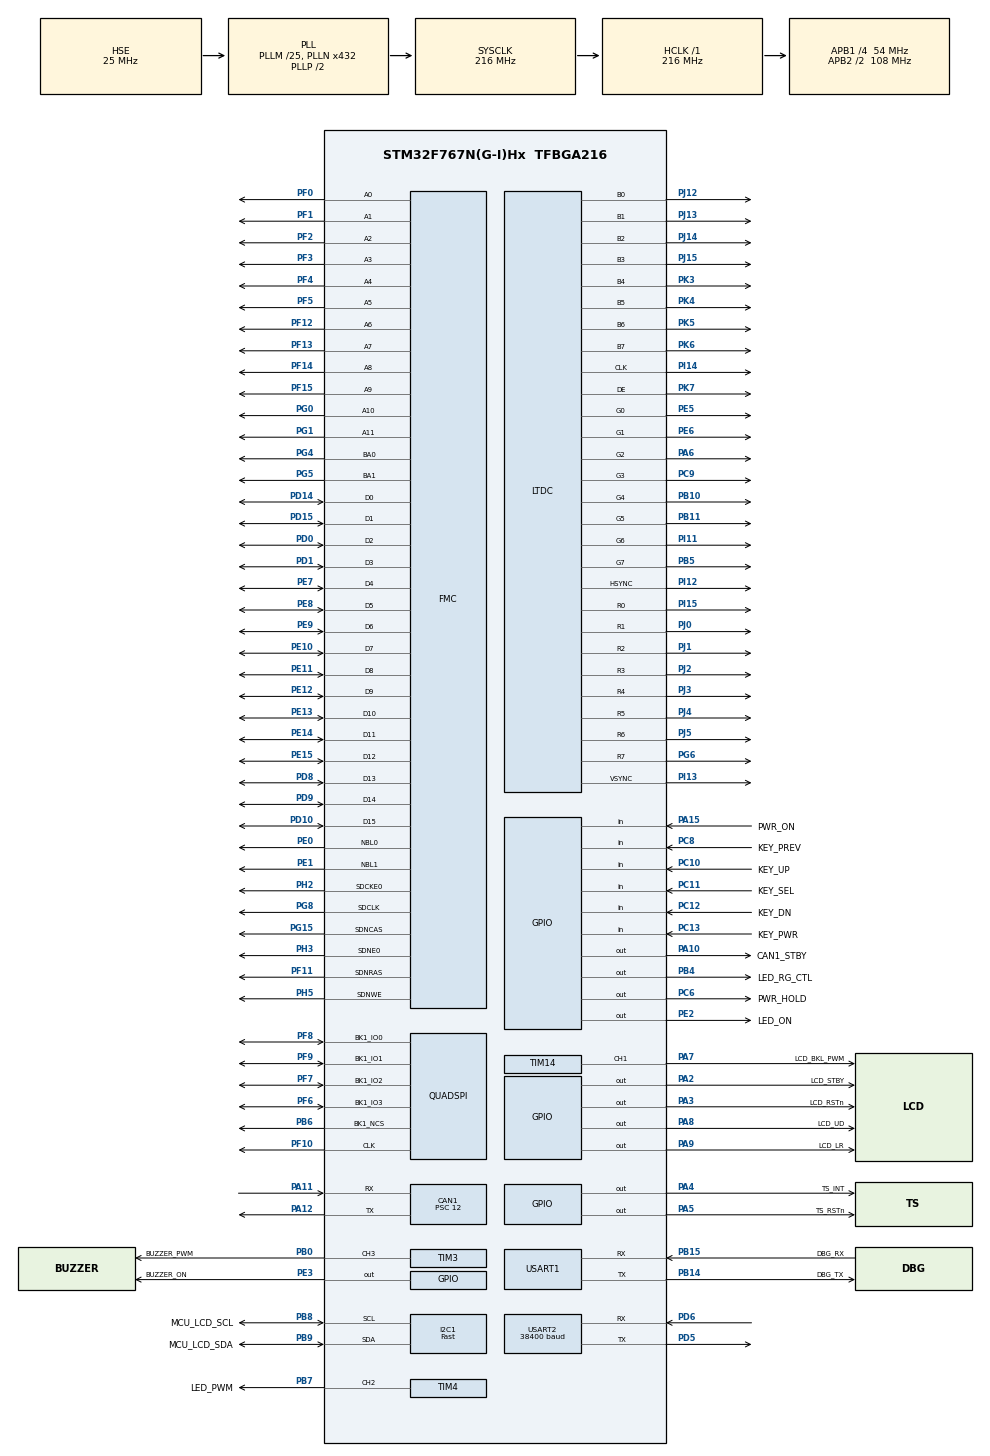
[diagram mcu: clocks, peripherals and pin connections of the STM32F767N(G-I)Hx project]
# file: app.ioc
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CAN1.ABOM=ENABLE
CAN1.AWUM=ENABLE
CAN1.BS1=CAN_BS1_15TQ
CAN1.BS2=CAN_BS2_2TQ
CAN1.CalculateBaudRate=250000
CAN1.CalculateTimeBit=4000
CAN1.CalculateTimeQuantum=222.22222222222223
CAN1.NART=ENABLE
CAN1.Prescaler=12
CAN1.TXFP=ENABLE
CORTEX_M7.CPU_DCache=Enabled
CORTEX_M7.CPU_ICache=Enabled
CORTEX_M7.MPU_Control=__NULL
CORTEX_M7.PREFETCH_ENABLE=1
CRC.InputDataFormat=CRC_INPUTDATA_FORMAT_WORDS
DMA2D.ColorMode=DMA2D_OUTPUT_RGB565
DMA2D.InputColorModeForeground=DMA2D_INPUT_RGB565
DMA2D.Mode=DMA2D_M2M
FMC.CASLatency1=FMC_SDRAM_CAS_LATENCY_3
FMC.ColumnBitsNumber1=FMC_SDRAM_COLUMN_BITS_NUM_9
FMC.ExitSelfRefreshDelay1=7
FMC.LoadToActiveDelay1=2
FMC.RCDDelay1=3
FMC.RPDelay1=3
FMC.RPDelay2=3
FMC.ReadBurst1=FMC_SDRAM_RBURST_ENABLE
FMC.RowCycleDelay1=10
FMC.RowCycleDelay2=10
FMC.SDClockPeriod1=FMC_SDRAM_CLOCK_PERIOD_2
FMC.SelfRefreshTime1=7
FMC.WriteProtection1=FMC_SDRAM_WRITE_PROTECTION_DISABLE
FMC.WriteRecoveryTime1=4
FREERTOS.Queues01=EcoQueueUART1,256,uint8_t,0,Static,EcoQueueUART1Buffer,EcoQueueUART1CtrlBlock;EcoQueueNMEA2KRX1,32,uint8_t,0,Static,EcoQueueNMEA2KRX1Buffer,EcoQueueNMEA2KRX1CtrlBlock;EcoQueueNMEA2KTX1,384,uint8_t,0,Static,EcoQueueNMEA2KTX1Buffer,EcoQueueNMEA2KTX1CtrlBlock
FREERTOS.Tasks01=EcoTaskMain,24,1024,runEcoTaskMain,As weak,NULL,Dynamic,NULL,NULL;EcoTaskUART,24,1024,runEcoTaskUART,As external,NULL,Dynamic,NULL,NULL;EcoTaskNMEA2KRx,24,1024,runEcoTaskNMEA2KRx,As external,NULL,Dynamic,NULL,NULL;EcoTaskNMEA2KTx,24,1024,runEcoTaskNMEA2KTx,As external,NULL,Dynamic,NULL,NULL;EcoTaskFlash,24,1024,runEcoTaskFlash,As external,NULL,Dynamic,NULL,NULL;EcoTaskKey,24,1024,runEcoTaskKey,As external,NULL,Dynamic,NULL,NULL;EcoTaskTGFX,24,4096,runEcoTaskTGFX,As external,NULL,Dynamic,NULL,NULL;EcoTackSync,24,1024,runEcoTaskSync,As external,NULL,Dynamic,NULL,NULL;EcoTaskControl,24,1024,runEcoTaskControl,As external,NULL,Dynamic,NULL,NULL
FREERTOS.configMINIMAL_STACK_SIZE=128
FREERTOS.configTOTAL_HEAP_SIZE=0xD000
FREERTOS.configUSE_NEWLIB_REENTRANT=1
I2C1.I2C_Speed_Mode=I2C_Fast
I2C1.Timing=0x6000030D
LTDC.ActiveW=800
LTDC.Alpha_L0=255
LTDC.Alpha_L1=255
LTDC.FBStartAdress_L0=0xC0000000
LTDC.FBStartAdress_L1=0xC0100000
LTDC.HBP=10
LTDC.HFP=10
LTDC.HSPolarity=LTDC_HSPOLARITY_AH
LTDC.HSync=14
LTDC.ImageHeight_L0=480
LTDC.ImageHeight_L1=480
LTDC.ImageWidth_L0=800
LTDC.Layers=0
LTDC.PCPolarity=LTDC_PCPOLARITY_IPC
LTDC.PixelFormat_L0=LTDC_PIXEL_FORMAT_RGB565
LTDC.PixelFormat_L1=LTDC_PIXEL_FORMAT_RGB565
LTDC.VBP=7
LTDC.VFP=7
LTDC.VSPolarity=LTDC_VSPOLARITY_AH
LTDC.VSync=7
LTDC.WindowX1_L0=800
LTDC.WindowX1_L1=800
LTDC.WindowY1_L0=480
LTDC.WindowY1_L1=480
Mcu.Family=STM32F7
Mcu.Name=STM32F767N(G-I)Hx
Mcu.Package=TFBGA216
NVIC.CAN1_RX0_IRQn=true\:5\:0\:false\:false\:true\:true\:true\:true\:true
NVIC.CAN1_TX_IRQn=true\:5\:0\:false\:false\:true\:true\:true\:true\:true
NVIC.DMA2D_IRQn=true\:5\:0\:false\:false\:true\:true\:true\:true\:true
NVIC.I2C1_EV_IRQn=true\:5\:0\:false\:false\:true\:true\:true\:true\:true
NVIC.LTDC_IRQn=true\:5\:0\:false\:false\:true\:true\:true\:true\:true
NVIC.PriorityGroup=NVIC_PRIORITYGROUP_4
NVIC.TIM6_DAC_IRQn=true\:15\:0\:false\:false\:true\:false\:false\:true\:true
NVIC.TIM7_IRQn=true\:5\:0\:false\:false\:true\:true\:true\:true\:true
NVIC.TimeBase=TIM6_DAC_IRQn
NVIC.TimeBaseIP=TIM6
NVIC.USART1_IRQn=true\:5\:0\:false\:false\:true\:true\:true\:true\:true
NVIC.USART2_IRQn=true\:5\:0\:false\:false\:true\:true\:true\:true\:true
PA10.GPIO_Label=CAN1_STBY
PA10.Signal=GPIO_Output
PA11.Mode=CAN_Activate
PA11.Signal=CAN1_RX
PA12.Mode=CAN_Activate
PA12.Signal=CAN1_TX
PA13.Mode=Trace_Asynchronous_SW
PA13.Signal=SYS_JTMS-SWDIO
PA14.Mode=Trace_Asynchronous_SW
PA14.Signal=SYS_JTCK-SWCLK
PA15.GPIO_Label=PWR_ON
PA15.Signal=GPIO_Input
PA2.GPIO_Label=LCD_STBY
PA2.Signal=GPIO_Output
PA3.GPIO_Label=LCD_RSTn
PA3.PinState=GPIO_PIN_RESET
PA3.Signal=GPIO_Output
PA4.GPIO_Label=TS_INT
PA4.Signal=GPIO_Output
PA5.GPIO_Label=TS_RSTn
PA5.Signal=GPIO_Output
PA6.Mode=RGB888
PA6.Signal=LTDC_G2
PA7.GPIO_Label=LCD_BKL_PWM
PA7.Signal=S_TIM14_CH1
PA8.GPIO_Label=LCD_UD
PA8.PinState=GPIO_PIN_SET
PA8.Signal=GPIO_Output
PA9.GPIO_Label=LCD_LR
PA9.PinState=GPIO_PIN_SET
PA9.Signal=GPIO_Output
PB0.GPIO_Label=BUZZER_PWM
PB0.Signal=S_TIM3_CH3
PB10.Mode=RGB888
PB10.Signal=LTDC_G4
PB11.Mode=RGB888
PB11.Signal=LTDC_G5
PB14.GPIO_Label=DBG_TX
PB14.Mode=Asynchronous
PB14.Signal=USART1_TX
PB15.GPIO_Label=DBG_RX
PB15.Mode=Asynchronous
PB15.Signal=USART1_RX
PB3.Mode=Trace_Asynchronous_SW
PB3.Signal=SYS_JTDO-SWO
PB4.GPIO_Label=LED_RG_CTL
PB4.Signal=GPIO_Output
PB5.Mode=RGB888
PB5.Signal=LTDC_G7
PB6.GPIO_PuPd=GPIO_PULLUP
PB6.Mode=Single Bank 1
PB6.Signal=QUADSPI_BK1_NCS
PB7.GPIO_Label=LED_PWM
PB7.Signal=S_TIM4_CH2
PB8.GPIO_Label=MCU_LCD_SCL
PB8.Mode=I2C
PB8.Signal=I2C1_SCL
PB9.GPIO_Label=MCU_LCD_SDA
PB9.Mode=I2C
PB9.Signal=I2C1_SDA
PC10.GPIO_Label=KEY_UP
PC10.Signal=GPIO_Input
PC11.GPIO_Label=KEY_SEL
PC11.Signal=GPIO_Input
PC12.GPIO_Label=KEY_DN
PC12.Signal=GPIO_Input
PC13.GPIO_Label=KEY_PWR
PC13.GPIO_PuPd=GPIO_PULLUP
PC13.Signal=GPIO_Input
PC6.GPIO_Label=PWR_HOLD
PC6.Signal=GPIO_Output
PC8.GPIO_Label=KEY_PREV
PC8.Signal=GPIO_Input
PC9.Mode=RGB888
PC9.Signal=LTDC_G3
PD0.Signal=FMC_D2_DA2
PD1.Signal=FMC_D3_DA3
PD10.Signal=FMC_D15_DA15
PD14.Signal=FMC_D0_DA0
PD15.Signal=FMC_D1_DA1
PD5.Mode=Asynchronous
PD5.Signal=USART2_TX
PD6.Mode=Asynchronous
PD6.Signal=USART2_RX
PD8.Signal=FMC_D13_DA13
PD9.Signal=FMC_D14_DA14
PE0.Signal=FMC_NBL0
PE1.Signal=FMC_NBL1
PE10.Signal=FMC_D7_DA7
PE11.Signal=FMC_D8_DA8
PE12.Signal=FMC_D9_DA9
PE13.Signal=FMC_D10_DA10
PE14.Signal=FMC_D11_DA11
PE15.Signal=FMC_D12_DA12
PE2.GPIO_Label=LED_ON
PE2.PinState=GPIO_PIN_RESET
PE2.Signal=GPIO_Output
PE3.GPIO_Label=BUZZER_ON
PE3.GPIO_Speed=GPIO_SPEED_FREQ_HIGH
PE3.Signal=GPIO_Output
PE5.Mode=RGB888
PE5.Signal=LTDC_G0
PE6.Mode=RGB888
PE6.Signal=LTDC_G1
PE7.Signal=FMC_D4_DA4
PE8.Signal=FMC_D5_DA5
PE9.Signal=FMC_D6_DA6
PF0.Signal=FMC_A0
PF1.Signal=FMC_A1
PF10.Mode=Single Bank 1
PF10.Signal=QUADSPI_CLK
PF11.Signal=FMC_SDNRAS
PF12.Signal=FMC_A6
PF13.Signal=FMC_A7
PF14.Signal=FMC_A8
PF15.Signal=FMC_A9
PF2.Signal=FMC_A2
PF3.Signal=FMC_A3
PF4.Signal=FMC_A4
PF5.Signal=FMC_A5
PF6.Mode=Single Bank 1
PF6.Signal=QUADSPI_BK1_IO3
PF7.Mode=Single Bank 1
PF7.Signal=QUADSPI_BK1_IO2
PF8.Mode=Single Bank 1
PF8.Signal=QUADSPI_BK1_IO0
PF9.Mode=Single Bank 1
PF9.Signal=QUADSPI_BK1_IO1
PG0.Signal=FMC_A10
PG1.Signal=FMC_A11
PG15.Signal=FMC_SDNCAS
PG4.Signal=FMC_A14_BA0
PG5.Signal=FMC_A15_BA1
PG6.Mode=RGB888
PG6.Signal=LTDC_R7
PG8.Signal=FMC_SDCLK
PH0/OSC_IN.Mode=HSE-External-Oscillator
PH0/OSC_IN.Signal=RCC_OSC_IN
PH1/OSC_OUT.Mode=HSE-External-Oscillator
PH1/OSC_OUT.Signal=RCC_OSC_OUT
PH2.Mode=SdramChipSelect1_1
PH2.Signal=FMC_SDCKE0
PH3.Mode=SdramChipSelect1_1
PH3.Signal=FMC_SDNE0
PH5.Signal=FMC_SDNWE
PI11.Mode=RGB888
PI11.Signal=LTDC_G6
PI12.GPIO_Speed=GPIO_SPEED_FREQ_LOW
PI12.Mode=RGB888
PI12.Signal=LTDC_HSYNC
PI13.GPIO_Speed=GPIO_SPEED_FREQ_LOW
PI13.Mode=RGB888
PI13.Signal=LTDC_VSYNC
PI14.GPIO_Speed=GPIO_SPEED_FREQ_LOW
PI14.Mode=RGB888
PI14.Signal=LTDC_CLK
PI15.Mode=RGB888
PI15.Signal=LTDC_R0
PJ0.Mode=RGB888
PJ0.Signal=LTDC_R1
PJ1.Mode=RGB888
PJ1.Signal=LTDC_R2
PJ12.Mode=RGB888
PJ12.Signal=LTDC_B0
PJ13.Mode=RGB888
PJ13.Signal=LTDC_B1
PJ14.Mode=RGB888
PJ14.Signal=LTDC_B2
PJ15.Mode=RGB888
PJ15.Signal=LTDC_B3
PJ2.Mode=RGB888
PJ2.Signal=LTDC_R3
PJ3.Mode=RGB888
PJ3.Signal=LTDC_R4
PJ4.Mode=RGB888
PJ4.Signal=LTDC_R5
PJ5.Mode=RGB888
PJ5.Signal=LTDC_R6
PK3.Mode=RGB888
PK3.Signal=LTDC_B4
PK4.Mode=RGB888
PK4.Signal=LTDC_B5
PK5.Mode=RGB888
PK5.Signal=LTDC_B6
PK6.Mode=RGB888
PK6.Signal=LTDC_B7
PK7.Mode=RGB888
PK7.Signal=LTDC_DE
ProjectManager.HeapSize=0x1000
ProjectManager.StackSize=0x1000
ProjectManager.TargetToolchain=STM32CubeIDE
QUADSPI.ChipSelectHighTime=QSPI_CS_HIGH_TIME_6_CYCLE
QUADSPI.ClockPrescaler=1
QUADSPI.FifoThreshold=6
QUADSPI.FlashSize=24
QUADSPI.SampleShifting=QSPI_SAMPLE_SHIFTING_HALFCYCLE
RCC.AHBFreq_Value=216000000
RCC.APB1CLKDivider=RCC_HCLK_DIV4
RCC.APB1Freq_Value=54000000
RCC.APB1TimFreq_Value=108000000
RCC.APB2CLKDivider=RCC_HCLK_DIV2
RCC.APB2Freq_Value=108000000
RCC.APB2TimFreq_Value=216000000
RCC.CortexFreq_Value=216000000
RCC.HCLKFreq_Value=216000000
RCC.HSE_VALUE=25000000
RCC.HSI_VALUE=16000000
RCC.LSE_VALUE=32768
RCC.PLLM=25
RCC.PLLN=432
RCC.PLLSAIN=400
RCC.PLLSAIR=4
RCC.PLLSAIRDiv=RCC_PLLSAIDIVR_4
RCC.PLLSourceVirtual=RCC_PLLSOURCE_HSE
RCC.SYSCLKFreq_VALUE=216000000
RCC.SYSCLKSource=RCC_SYSCLKSOURCE_PLLCLK
RCC.USBFreq_Value=216000000
RCC.VCOOutputFreq_Value=432000000
SH.FMC_A0.0=FMC_A0,12b-sda1
SH.FMC_A1.0=FMC_A1,12b-sda1
SH.FMC_A10.0=FMC_A10,12b-sda1
SH.FMC_A11.0=FMC_A11,12b-sda1
SH.FMC_A14_BA0.0=FMC_BA0,FourSdramBanks1
SH.FMC_A15_BA1.0=FMC_BA1,FourSdramBanks1
SH.FMC_A2.0=FMC_A2,12b-sda1
SH.FMC_A3.0=FMC_A3,12b-sda1
SH.FMC_A4.0=FMC_A4,12b-sda1
SH.FMC_A5.0=FMC_A5,12b-sda1
SH.FMC_A6.0=FMC_A6,12b-sda1
SH.FMC_A7.0=FMC_A7,12b-sda1
SH.FMC_A8.0=FMC_A8,12b-sda1
SH.FMC_A9.0=FMC_A9,12b-sda1
SH.FMC_D0_DA0.0=FMC_D0,sd-16b-d1
SH.FMC_D10_DA10.0=FMC_D10,sd-16b-d1
SH.FMC_D11_DA11.0=FMC_D11,sd-16b-d1
SH.FMC_D12_DA12.0=FMC_D12,sd-16b-d1
SH.FMC_D13_DA13.0=FMC_D13,sd-16b-d1
SH.FMC_D14_DA14.0=FMC_D14,sd-16b-d1
SH.FMC_D15_DA15.0=FMC_D15,sd-16b-d1
SH.FMC_D1_DA1.0=FMC_D1,sd-16b-d1
SH.FMC_D2_DA2.0=FMC_D2,sd-16b-d1
SH.FMC_D3_DA3.0=FMC_D3,sd-16b-d1
SH.FMC_D4_DA4.0=FMC_D4,sd-16b-d1
SH.FMC_D5_DA5.0=FMC_D5,sd-16b-d1
SH.FMC_D6_DA6.0=FMC_D6,sd-16b-d1
SH.FMC_D7_DA7.0=FMC_D7,sd-16b-d1
SH.FMC_D8_DA8.0=FMC_D8,sd-16b-d1
SH.FMC_D9_DA9.0=FMC_D9,sd-16b-d1
SH.FMC_NBL0.0=FMC_NBL0,Sd2ByteEnable1
SH.FMC_NBL1.0=FMC_NBL1,Sd2ByteEnable1
SH.FMC_SDCLK.0=FMC_SDCLK,12b-sda1
SH.FMC_SDNCAS.0=FMC_SDNCAS,12b-sda1
SH.FMC_SDNRAS.0=FMC_SDNRAS,12b-sda1
SH.FMC_SDNWE.0=FMC_SDNWE,12b-sda1
SH.S_TIM14_CH1.0=TIM14_CH1,PWM Generation1 CH1
SH.S_TIM3_CH3.0=TIM3_CH3,PWM Generation3 CH3
SH.S_TIM4_CH2.0=TIM4_CH2,PWM Generation2 CH2
STMicroelectronics.X-CUBE-TOUCHGFX.4.25.0.ApplicationCcGraphicsJjApplication=TouchGFXOoGenerator
STMicroelectronics.X-CUBE-TOUCHGFX.4.25.0.tgfx_address1=0xC0000000
STMicroelectronics.X-CUBE-TOUCHGFX.4.25.0.tgfx_address2=0xC0100000
STMicroelectronics.X-CUBE-TOUCHGFX.4.25.0.tgfx_buffering_strategy=Double
STMicroelectronics.X-CUBE-TOUCHGFX.4.25.0.tgfx_display_interface=disp_ltdc
STMicroelectronics.X-CUBE-TOUCHGFX.4.25.0.tgfx_hardware_accelerator=dma_2d
STMicroelectronics.X-CUBE-TOUCHGFX.4.25.0.tgfx_location=By Address
STMicroelectronics.X-CUBE-TOUCHGFX.4.25.0.tgfx_vector_rendering=Disabled
STMicroelectronics.X-CUBE-TOUCHGFX.4.25.0.tgfx_vsync=vsync_ltdc
STMicroelectronics.X-CUBE-TOUCHGFX.4.25.0_IsPackSelfContextualization=true
TIM14.Channel=TIM_CHANNEL_1
TIM14.Period=100-1
TIM14.Prescaler=108-1
TIM14.Pulse=100-1
TIM3.AutoReloadPreload=TIM_AUTORELOAD_PRELOAD_ENABLE
TIM3.Channel-PWM\ Generation3\ CH3=TIM_CHANNEL_3
TIM3.Period=250-1
TIM3.Prescaler=108-1
TIM3.Pulse-PWM\ Generation3\ CH3=0
TIM4.AutoReloadPreload=TIM_AUTORELOAD_PRELOAD_ENABLE
TIM4.Channel-PWM\ Generation2\ CH2=TIM_CHANNEL_2
TIM4.Period=32768-1
TIM4.Prescaler=33-1
TIM4.Pulse-PWM\ Generation2\ CH2=256
TIM7.AutoReloadPreload=TIM_AUTORELOAD_PRELOAD_ENABLE
TIM7.Period=10000-1
TIM7.Prescaler=10800-1
USART1.VirtualMode-Asynchronous=VM_ASYNC
USART2.BaudRate=38400
USART2.VirtualMode-Asynchronous=VM_ASYNC
VP_CRC_VS_CRC.Mode=CRC_Activate
VP_DMA2D_VS_DMA2D.Mode=DMA2D_Activate
VP_FREERTOS_VS_CMSIS_V2.Mode=CMSIS_V2
VP_STMicroelectronics.X-CUBE-TOUCHGFX_VS_GraphicsJjApplication_4.25.0.Mode=GraphicsJjApplication
VP_SYS_VS_tim6.Mode=TIM6
VP_TIM14_VS_ClockSourceINT.Mode=Enable_Timer
VP_TIM3_VS_ClockSourceINT.Mode=Internal
VP_TIM4_VS_ClockSourceINT.Mode=Internal
VP_TIM7_VS_ClockSourceINT.Mode=Enable_Timer
board=custom

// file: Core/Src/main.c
/* USER CODE BEGIN Header */
/**
  ******************************************************************************
  * @file           : main.c
  * @brief          : Main program body
  ******************************************************************************
  * @attention
  *
  * Copyright (c) 2023 STMicroelectronics.
  * All rights reserved.
  *
  * This software is licensed under terms that can be found in the LICENSE file
  * in the root directory of this software component.
  * If no LICENSE file comes with this software, it is provided AS-IS.
  *
  ******************************************************************************
  */
/* USER CODE END Header */
#include "main.h"
#include "cmsis_os.h"
#include "app_touchgfx.h"

/* USER CODE BEGIN Includes */
#include "eco.h"
/* USER CODE END Includes */

typedef StaticQueue_t osStaticMessageQDef_t;

CAN_HandleTypeDef hcan1;

CRC_HandleTypeDef hcrc;

DMA2D_HandleTypeDef hdma2d;

I2C_HandleTypeDef hi2c1;

LTDC_HandleTypeDef hltdc;

QSPI_HandleTypeDef hqspi;

TIM_HandleTypeDef htim3;
TIM_HandleTypeDef htim4;
TIM_HandleTypeDef htim7;
TIM_HandleTypeDef htim14;

UART_HandleTypeDef huart1;
UART_HandleTypeDef huart2;

SDRAM_HandleTypeDef hsdram1;

/* Definitions for EcoTaskMain */
osThreadId_t EcoTaskMainHandle;
const osThreadAttr_t EcoTaskMain_attributes = {
  .name = "EcoTaskMain",
  .stack_size = 1024 * 4,
  .priority = (osPriority_t) osPriorityNormal,
};
/* Definitions for EcoTaskUART */
osThreadId_t EcoTaskUARTHandle;
const osThreadAttr_t EcoTaskUART_attributes = {
  .name = "EcoTaskUART",
  .stack_size = 1024 * 4,
  .priority = (osPriority_t) osPriorityNormal,
};
/* Definitions for EcoTaskNMEA2KRx */
osThreadId_t EcoTaskNMEA2KRxHandle;
const osThreadAttr_t EcoTaskNMEA2KRx_attributes = {
  .name = "EcoTaskNMEA2KRx",
  .stack_size = 1024 * 4,
  .priority = (osPriority_t) osPriorityNormal,
};
/* Definitions for EcoTaskNMEA2KTx */
osThreadId_t EcoTaskNMEA2KTxHandle;
const osThreadAttr_t EcoTaskNMEA2KTx_attributes = {
  .name = "EcoTaskNMEA2KTx",
  .stack_size = 1024 * 4,
  .priority = (osPriority_t) osPriorityNormal,
};
/* Definitions for EcoTaskFlash */
osThreadId_t EcoTaskFlashHandle;
const osThreadAttr_t EcoTaskFlash_attributes = {
  .name = "EcoTaskFlash",
  .stack_size = 1024 * 4,
  .priority = (osPriority_t) osPriorityNormal,
};
/* Definitions for EcoTaskKey */
osThreadId_t EcoTaskKeyHandle;
const osThreadAttr_t EcoTaskKey_attributes = {
  .name = "EcoTaskKey",
  .stack_size = 1024 * 4,
  .priority = (osPriority_t) osPriorityNormal,
};
/* Definitions for EcoTaskTGFX */
osThreadId_t EcoTaskTGFXHandle;
const osThreadAttr_t EcoTaskTGFX_attributes = {
  .name = "EcoTaskTGFX",
  .stack_size = 4096 * 4,
  .priority = (osPriority_t) osPriorityNormal,
};
/* Definitions for EcoTackSync */
osThreadId_t EcoTackSyncHandle;
const osThreadAttr_t EcoTackSync_attributes = {
  .name = "EcoTackSync",
  .stack_size = 1024 * 4,
  .priority = (osPriority_t) osPriorityNormal,
};
/* Definitions for EcoTaskControl */
osThreadId_t EcoTaskControlHandle;
const osThreadAttr_t EcoTaskControl_attributes = {
  .name = "EcoTaskControl",
  .stack_size = 1024 * 4,
  .priority = (osPriority_t) osPriorityNormal,
};
/* Definitions for EcoQueueUART1 */
osMessageQueueId_t EcoQueueUART1Handle;
uint8_t EcoQueueUART1Buffer[ 256 * sizeof( uint8_t ) ];
osStaticMessageQDef_t EcoQueueUART1CtrlBlock;
const osMessageQueueAttr_t EcoQueueUART1_attributes = {
  .name = "EcoQueueUART1",
  .cb_mem = &EcoQueueUART1CtrlBlock,
  .cb_size = sizeof(EcoQueueUART1CtrlBlock),
  .mq_mem = &EcoQueueUART1Buffer,
  .mq_size = sizeof(EcoQueueUART1Buffer)
};
/* Definitions for EcoQueueNMEA2KRX1 */
osMessageQueueId_t EcoQueueNMEA2KRX1Handle;
uint8_t EcoQueueNMEA2KRX1Buffer[ 32 * sizeof( uint8_t ) ];
osStaticMessageQDef_t EcoQueueNMEA2KRX1CtrlBlock;
const osMessageQueueAttr_t EcoQueueNMEA2KRX1_attributes = {
  .name = "EcoQueueNMEA2KRX1",
  .cb_mem = &EcoQueueNMEA2KRX1CtrlBlock,
  .cb_size = sizeof(EcoQueueNMEA2KRX1CtrlBlock),
  .mq_mem = &EcoQueueNMEA2KRX1Buffer,
  .mq_size = sizeof(EcoQueueNMEA2KRX1Buffer)
};
/* Definitions for EcoQueueNMEA2KTX1 */
osMessageQueueId_t EcoQueueNMEA2KTX1Handle;
uint8_t EcoQueueNMEA2KTX1Buffer[ 384 * sizeof( uint8_t ) ];
osStaticMessageQDef_t EcoQueueNMEA2KTX1CtrlBlock;
const osMessageQueueAttr_t EcoQueueNMEA2KTX1_attributes = {
  .name = "EcoQueueNMEA2KTX1",
  .cb_mem = &EcoQueueNMEA2KTX1CtrlBlock,
  .cb_size = sizeof(EcoQueueNMEA2KTX1CtrlBlock),
  .mq_mem = &EcoQueueNMEA2KTX1Buffer,
  .mq_size = sizeof(EcoQueueNMEA2KTX1Buffer)
};

void SystemClock_Config(void);
static void MX_GPIO_Init(void);
static void MX_USART1_UART_Init(void);
static void MX_I2C1_Init(void);
static void MX_CAN1_Init(void);
static void MX_QUADSPI_Init(void);
static void MX_CRC_Init(void);
static void MX_DMA2D_Init(void);
static void MX_FMC_Init(void);
static void MX_LTDC_Init(void);
static void MX_TIM3_Init(void);
static void MX_USART2_UART_Init(void);
static void MX_TIM4_Init(void);
static void MX_TIM7_Init(void);
static void MX_TIM14_Init(void);
void runEcoTaskMain(void *argument);
extern void runEcoTaskUART(void *argument);
extern void runEcoTaskNMEA2KRx(void *argument);
extern void runEcoTaskNMEA2KTx(void *argument);
extern void runEcoTaskFlash(void *argument);
extern void runEcoTaskKey(void *argument);
extern void runEcoTaskTGFX(void *argument);
extern void runEcoTaskSync(void *argument);
extern void runEcoTaskControl(void *argument);

/* USER CODE BEGIN PFP */
void SystemClock_pwrsav_Config(void);
/* USER CODE END PFP */

int main(void)
{

  /* Enable the CPU Cache */

  /* Enable I-Cache---------------------------------------------------------*/
  SCB_EnableICache();

  /* Enable D-Cache---------------------------------------------------------*/
  SCB_EnableDCache();

  /* MCU Configuration--------------------------------------------------------*/

  /* Reset of all peripherals, Initializes the Flash interface and the Systick. */
  HAL_Init();

  /* Configure the system clock */
  SystemClock_Config();

  /* Initialize all configured peripherals */
  MX_GPIO_Init();
  MX_USART1_UART_Init();
  MX_I2C1_Init();
  MX_CAN1_Init();
  MX_QUADSPI_Init();
  MX_CRC_Init();
  MX_DMA2D_Init();
  MX_FMC_Init();
  MX_LTDC_Init();
  MX_TIM3_Init();
  MX_USART2_UART_Init();
  MX_TIM4_Init();
  MX_TIM7_Init();
  MX_TIM14_Init();
  MX_TouchGFX_Init();
  /* Call PreOsInit function */
  MX_TouchGFX_PreOSInit();

  /* Init scheduler */
  osKernelInitialize();

  /* Create the queue(s) */
  /* creation of EcoQueueUART1 */
  EcoQueueUART1Handle = osMessageQueueNew (256, sizeof(uint8_t), &EcoQueueUART1_attributes);

  /* creation of EcoQueueNMEA2KRX1 */
  EcoQueueNMEA2KRX1Handle = osMessageQueueNew (32, sizeof(uint8_t), &EcoQueueNMEA2KRX1_attributes);

  /* creation of EcoQueueNMEA2KTX1 */
  EcoQueueNMEA2KTX1Handle = osMessageQueueNew (384, sizeof(uint8_t), &EcoQueueNMEA2KTX1_attributes);

  /* Create the thread(s) */
  /* creation of EcoTaskMain */
  EcoTaskMainHandle = osThreadNew(runEcoTaskMain, NULL, &EcoTaskMain_attributes);

  /* creation of EcoTaskUART */
  EcoTaskUARTHandle = osThreadNew(runEcoTaskUART, NULL, &EcoTaskUART_attributes);

  /* creation of EcoTaskNMEA2KRx */
  EcoTaskNMEA2KRxHandle = osThreadNew(runEcoTaskNMEA2KRx, NULL, &EcoTaskNMEA2KRx_attributes);

  /* creation of EcoTaskNMEA2KTx */
  EcoTaskNMEA2KTxHandle = osThreadNew(runEcoTaskNMEA2KTx, NULL, &EcoTaskNMEA2KTx_attributes);

  /* creation of EcoTaskFlash */
  EcoTaskFlashHandle = osThreadNew(runEcoTaskFlash, NULL, &EcoTaskFlash_attributes);

  /* creation of EcoTaskKey */
  EcoTaskKeyHandle = osThreadNew(runEcoTaskKey, NULL, &EcoTaskKey_attributes);

  /* creation of EcoTaskTGFX */
  EcoTaskTGFXHandle = osThreadNew(runEcoTaskTGFX, NULL, &EcoTaskTGFX_attributes);

  /* creation of EcoTackSync */
  EcoTackSyncHandle = osThreadNew(runEcoTaskSync, NULL, &EcoTackSync_attributes);

  /* creation of EcoTaskControl */
  EcoTaskControlHandle = osThreadNew(runEcoTaskControl, NULL, &EcoTaskControl_attributes);

  /* Start scheduler */
  osKernelStart();

  /* We should never get here as control is now taken by the scheduler */

  /* Infinite loop */
  while (1)
  {

  }
}

void SystemClock_Config(void)
{
  RCC_OscInitTypeDef RCC_OscInitStruct = {0};
  RCC_ClkInitTypeDef RCC_ClkInitStruct = {0};

  /** Configure the main internal regulator output voltage
  */
  __HAL_RCC_PWR_CLK_ENABLE();
  __HAL_PWR_VOLTAGESCALING_CONFIG(PWR_REGULATOR_VOLTAGE_SCALE1);

  /** Initializes the RCC Oscillators according to the specified parameters
  * in the RCC_OscInitTypeDef structure.
  */
  RCC_OscInitStruct.OscillatorType = RCC_OSCILLATORTYPE_HSE;
  RCC_OscInitStruct.HSEState = RCC_HSE_ON;
  RCC_OscInitStruct.PLL.PLLState = RCC_PLL_ON;
  RCC_OscInitStruct.PLL.PLLSource = RCC_PLLSOURCE_HSE;
  RCC_OscInitStruct.PLL.PLLM = 25;
  RCC_OscInitStruct.PLL.PLLN = 432;
  RCC_OscInitStruct.PLL.PLLP = RCC_PLLP_DIV2;
  RCC_OscInitStruct.PLL.PLLQ = 2;
  RCC_OscInitStruct.PLL.PLLR = 2;
  if (HAL_RCC_OscConfig(&RCC_OscInitStruct) != HAL_OK)
  {
    Error_Handler();
  }

  /** Activate the Over-Drive mode
  */
  if (HAL_PWREx_EnableOverDrive() != HAL_OK)
  {
    Error_Handler();
  }

  /** Initializes the CPU, AHB and APB buses clocks
  */
  RCC_ClkInitStruct.ClockType = RCC_CLOCKTYPE_HCLK|RCC_CLOCKTYPE_SYSCLK
                              |RCC_CLOCKTYPE_PCLK1|RCC_CLOCKTYPE_PCLK2;
  RCC_ClkInitStruct.SYSCLKSource = RCC_SYSCLKSOURCE_PLLCLK;
  RCC_ClkInitStruct.AHBCLKDivider = RCC_SYSCLK_DIV1;
  RCC_ClkInitStruct.APB1CLKDivider = RCC_HCLK_DIV4;
  RCC_ClkInitStruct.APB2CLKDivider = RCC_HCLK_DIV2;

  if (HAL_RCC_ClockConfig(&RCC_ClkInitStruct, FLASH_LATENCY_7) != HAL_OK)
  {
    Error_Handler();
  }
}

static void MX_CAN1_Init(void)
{

  /* USER CODE BEGIN CAN1_Init 0 */
  CAN_FilterTypeDef  sFilterConfig;

  /* USER CODE END CAN1_Init 0 */

  hcan1.Instance = CAN1;
  hcan1.Init.Prescaler = 12;
  hcan1.Init.Mode = CAN_MODE_NORMAL;
  hcan1.Init.SyncJumpWidth = CAN_SJW_1TQ;
  hcan1.Init.TimeSeg1 = CAN_BS1_15TQ;
  hcan1.Init.TimeSeg2 = CAN_BS2_2TQ;
  hcan1.Init.TimeTriggeredMode = DISABLE;
  hcan1.Init.AutoBusOff = ENABLE;
  hcan1.Init.AutoWakeUp = ENABLE;
  hcan1.Init.AutoRetransmission = ENABLE;
  hcan1.Init.ReceiveFifoLocked = DISABLE;
  hcan1.Init.TransmitFifoPriority = ENABLE;
  if (HAL_CAN_Init(&hcan1) != HAL_OK)
  {
    Error_Handler();
  }
  /* USER CODE BEGIN CAN1_Init 2 */
  /* Configure the CAN Filter */
  sFilterConfig.FilterBank = 0;
  sFilterConfig.FilterMode = CAN_FILTERMODE_IDMASK;
  sFilterConfig.FilterScale = CAN_FILTERSCALE_32BIT;
  sFilterConfig.FilterIdHigh = 0x0000;
  sFilterConfig.FilterIdLow = 0x0000;
  sFilterConfig.FilterMaskIdHigh = 0x0000;
  sFilterConfig.FilterMaskIdLow = 0x0000;
  sFilterConfig.FilterFIFOAssignment = CAN_FILTER_FIFO0;
  sFilterConfig.FilterActivation = ENABLE;
  sFilterConfig.SlaveStartFilterBank = 14;

  /* Filter configuration Error */
  if(HAL_CAN_ConfigFilter(&hcan1, &sFilterConfig) != HAL_OK) Error_Handler();

  /* Start the CAN peripheral */
  if(HAL_CAN_Start(&hcan1) != HAL_OK) Error_Handler();

  /* Activate CAN RX notification */
  if (HAL_CAN_ActivateNotification(&hcan1, CAN_IT_RX_FIFO0_MSG_PENDING) != HAL_OK) Error_Handler();

  /* USER CODE END CAN1_Init 2 */

}

static void MX_CRC_Init(void)
{

  hcrc.Instance = CRC;
  hcrc.Init.DefaultPolynomialUse = DEFAULT_POLYNOMIAL_ENABLE;
  hcrc.Init.DefaultInitValueUse = DEFAULT_INIT_VALUE_ENABLE;
  hcrc.Init.InputDataInversionMode = CRC_INPUTDATA_INVERSION_NONE;
  hcrc.Init.OutputDataInversionMode = CRC_OUTPUTDATA_INVERSION_DISABLE;
  hcrc.InputDataFormat = CRC_INPUTDATA_FORMAT_WORDS;
  if (HAL_CRC_Init(&hcrc) != HAL_OK)
  {
    Error_Handler();
  }

}

static void MX_DMA2D_Init(void)
{

  hdma2d.Instance = DMA2D;
  hdma2d.Init.Mode = DMA2D_M2M;
  hdma2d.Init.ColorMode = DMA2D_OUTPUT_RGB565;
  hdma2d.Init.OutputOffset = 0;
  hdma2d.LayerCfg[1].InputOffset = 0;
  hdma2d.LayerCfg[1].InputColorMode = DMA2D_INPUT_RGB565;
  hdma2d.LayerCfg[1].AlphaMode = DMA2D_NO_MODIF_ALPHA;
  hdma2d.LayerCfg[1].InputAlpha = 0;
  hdma2d.LayerCfg[1].AlphaInverted = DMA2D_REGULAR_ALPHA;
  hdma2d.LayerCfg[1].RedBlueSwap = DMA2D_RB_REGULAR;
  if (HAL_DMA2D_Init(&hdma2d) != HAL_OK)
  {
    Error_Handler();
  }
  if (HAL_DMA2D_ConfigLayer(&hdma2d, 1) != HAL_OK)
  {
    Error_Handler();
  }

}

static void MX_I2C1_Init(void)
{

  hi2c1.Instance = I2C1;
  hi2c1.Init.Timing = 0x6000030D;
  hi2c1.Init.OwnAddress1 = 0;
  hi2c1.Init.AddressingMode = I2C_ADDRESSINGMODE_7BIT;
  hi2c1.Init.DualAddressMode = I2C_DUALADDRESS_DISABLE;
  hi2c1.Init.OwnAddress2 = 0;
  hi2c1.Init.OwnAddress2Masks = I2C_OA2_NOMASK;
  hi2c1.Init.GeneralCallMode = I2C_GENERALCALL_DISABLE;
  hi2c1.Init.NoStretchMode = I2C_NOSTRETCH_DISABLE;
  if (HAL_I2C_Init(&hi2c1) != HAL_OK)
  {
    Error_Handler();
  }

  /** Configure Analogue filter
  */
  if (HAL_I2CEx_ConfigAnalogFilter(&hi2c1, I2C_ANALOGFILTER_ENABLE) != HAL_OK)
  {
    Error_Handler();
  }

  /** Configure Digital filter
  */
  if (HAL_I2CEx_ConfigDigitalFilter(&hi2c1, 0) != HAL_OK)
  {
    Error_Handler();
  }
  /* USER CODE BEGIN I2C1_Init 2 */

  initTouchSensor();

  /* USER CODE END I2C1_Init 2 */

}

static void MX_LTDC_Init(void)
{

  LTDC_LayerCfgTypeDef pLayerCfg = {0};

  /* USER CODE BEGIN LTDC_Init 1 */
  HAL_GPIO_WritePin(LCD_RSTn_GPIO_Port, LCD_RSTn_Pin, GPIO_PIN_RESET);
  HAL_Delay(10);
  HAL_GPIO_WritePin(LCD_RSTn_GPIO_Port, LCD_RSTn_Pin, GPIO_PIN_SET);
  if(g_board_id == BOARD_ID_ACU15)
  {
      HAL_Delay(5);
      HAL_GPIO_WritePin(LCD_STBY_GPIO_Port, LCD_STBY_Pin, GPIO_PIN_SET);
  }

  /* USER CODE END LTDC_Init 1 */
  hltdc.Instance = LTDC;
  hltdc.Init.HSPolarity = LTDC_HSPOLARITY_AH;
  hltdc.Init.VSPolarity = LTDC_VSPOLARITY_AH;
  hltdc.Init.DEPolarity = LTDC_DEPOLARITY_AL;
  hltdc.Init.PCPolarity = LTDC_PCPOLARITY_IPC;
  hltdc.Init.HorizontalSync = 13;
  hltdc.Init.VerticalSync = 6;
  hltdc.Init.AccumulatedHBP = 23;
  hltdc.Init.AccumulatedVBP = 13;
  hltdc.Init.AccumulatedActiveW = 823;
  hltdc.Init.AccumulatedActiveH = 493;
  hltdc.Init.TotalWidth = 833;
  hltdc.Init.TotalHeigh = 500;
  hltdc.Init.Backcolor.Blue = 0;
  hltdc.Init.Backcolor.Green = 0;
  hltdc.Init.Backcolor.Red = 0;
  if (HAL_LTDC_Init(&hltdc) != HAL_OK)
  {
    Error_Handler();
  }
  pLayerCfg.WindowX0 = 0;
  pLayerCfg.WindowX1 = 800;
  pLayerCfg.WindowY0 = 0;
  pLayerCfg.WindowY1 = 480;
  pLayerCfg.PixelFormat = LTDC_PIXEL_FORMAT_RGB565;
  pLayerCfg.Alpha = 255;
  pLayerCfg.Alpha0 = 0;
  pLayerCfg.BlendingFactor1 = LTDC_BLENDING_FACTOR1_CA;
  pLayerCfg.BlendingFactor2 = LTDC_BLENDING_FACTOR2_CA;
  pLayerCfg.FBStartAdress = 0xC0000000;
  pLayerCfg.ImageWidth = 800;
  pLayerCfg.ImageHeight = 480;
  pLayerCfg.Backcolor.Blue = 0;
  pLayerCfg.Backcolor.Green = 0;
  pLayerCfg.Backcolor.Red = 0;
  if (HAL_LTDC_ConfigLayer(&hltdc, &pLayerCfg, 0) != HAL_OK)
  {
    Error_Handler();
  }
  /* USER CODE BEGIN LTDC_Init 2 */
  if(g_board_id == BOARD_ID_ACU10)
  {
      hltdc.Instance = LTDC;
      hltdc.Init.HSPolarity = LTDC_HSPOLARITY_AL;
      hltdc.Init.VSPolarity = LTDC_VSPOLARITY_AL;
      hltdc.Init.DEPolarity = LTDC_DEPOLARITY_AL;
      hltdc.Init.PCPolarity = LTDC_PCPOLARITY_IPC;
      hltdc.Init.HorizontalSync = 6;
      hltdc.Init.VerticalSync = 6;
      hltdc.Init.AccumulatedHBP = 13;
      hltdc.Init.AccumulatedVBP = 13;
      hltdc.Init.AccumulatedActiveW = 493;
      hltdc.Init.AccumulatedActiveH = 493;
      hltdc.Init.TotalWidth = 500;
      hltdc.Init.TotalHeigh = 500;
      hltdc.Init.Backcolor.Blue = 0;
      hltdc.Init.Backcolor.Green = 0;
      hltdc.Init.Backcolor.Red = 0;
      if (HAL_LTDC_Init(&hltdc) != HAL_OK)
      {
        Error_Handler();
      }
      pLayerCfg.WindowX0 = 0;
      pLayerCfg.WindowX1 = 480;
      pLayerCfg.WindowY0 = 0;
      pLayerCfg.WindowY1 = 480;
      pLayerCfg.PixelFormat = LTDC_PIXEL_FORMAT_RGB565;
      pLayerCfg.Alpha = 255;
      pLayerCfg.Alpha0 = 0;
      pLayerCfg.BlendingFactor1 = LTDC_BLENDING_FACTOR1_CA;
      pLayerCfg.BlendingFactor2 = LTDC_BLENDING_FACTOR2_CA;
      pLayerCfg.FBStartAdress = 0xC0000000;
      pLayerCfg.ImageWidth = 480;
      pLayerCfg.ImageHeight = 480;
      pLayerCfg.Backcolor.Blue = 0;
      pLayerCfg.Backcolor.Green = 0;
      pLayerCfg.Backcolor.Red = 0;
      if (HAL_LTDC_ConfigLayer(&hltdc, &pLayerCfg, 0) != HAL_OK)
      {
        Error_Handler();
      }
  }

//  pLayerCfg.FBStartAdress = (uint32_t)((uint32_t*)image_kitten_480x480);
//  HAL_LTDC_ConfigLayer(&hltdc, &pLayerCfg, 0);
  /* USER CODE END LTDC_Init 2 */

}

static void MX_QUADSPI_Init(void)
{

  /* QUADSPI parameter configuration*/
  hqspi.Instance = QUADSPI;
  hqspi.Init.ClockPrescaler = 1;
  hqspi.Init.FifoThreshold = 6;
  hqspi.Init.SampleShifting = QSPI_SAMPLE_SHIFTING_HALFCYCLE;
  hqspi.Init.FlashSize = 24;
  hqspi.Init.ChipSelectHighTime = QSPI_CS_HIGH_TIME_6_CYCLE;
  hqspi.Init.ClockMode = QSPI_CLOCK_MODE_0;
  hqspi.Init.FlashID = QSPI_FLASH_ID_1;
  hqspi.Init.DualFlash = QSPI_DUALFLASH_DISABLE;
  if (HAL_QSPI_Init(&hqspi) != HAL_OK)
  {
    Error_Handler();
  }
  /* USER CODE BEGIN QUADSPI_Init 2 */
  initQSPI();
  /* USER CODE END QUADSPI_Init 2 */

}

static void MX_TIM3_Init(void)
{

  TIM_ClockConfigTypeDef sClockSourceConfig = {0};
  TIM_MasterConfigTypeDef sMasterConfig = {0};
  TIM_OC_InitTypeDef sConfigOC = {0};

  htim3.Instance = TIM3;
  htim3.Init.Prescaler = 108-1;
  htim3.Init.CounterMode = TIM_COUNTERMODE_UP;
  htim3.Init.Period = 250-1;
  htim3.Init.ClockDivision = TIM_CLOCKDIVISION_DIV1;
  htim3.Init.AutoReloadPreload = TIM_AUTORELOAD_PRELOAD_ENABLE;
  if (HAL_TIM_Base_Init(&htim3) != HAL_OK)
  {
    Error_Handler();
  }
  sClockSourceConfig.ClockSource = TIM_CLOCKSOURCE_INTERNAL;
  if (HAL_TIM_ConfigClockSource(&htim3, &sClockSourceConfig) != HAL_OK)
  {
    Error_Handler();
  }
  if (HAL_TIM_PWM_Init(&htim3) != HAL_OK)
  {
    Error_Handler();
  }
  sMasterConfig.MasterOutputTrigger = TIM_TRGO_RESET;
  sMasterConfig.MasterSlaveMode = TIM_MASTERSLAVEMODE_DISABLE;
  if (HAL_TIMEx_MasterConfigSynchronization(&htim3, &sMasterConfig) != HAL_OK)
  {
    Error_Handler();
  }
  sConfigOC.OCMode = TIM_OCMODE_PWM1;
  sConfigOC.Pulse = 0;
  sConfigOC.OCPolarity = TIM_OCPOLARITY_HIGH;
  sConfigOC.OCFastMode = TIM_OCFAST_DISABLE;
  if (HAL_TIM_PWM_ConfigChannel(&htim3, &sConfigOC, TIM_CHANNEL_3) != HAL_OK)
  {
    Error_Handler();
  }
  /* USER CODE BEGIN TIM3_Init 2 */
  HAL_TIM_PWM_Start(&htim3, TIM_CHANNEL_3);
  /* USER CODE END TIM3_Init 2 */
  HAL_TIM_MspPostInit(&htim3);

}

static void MX_TIM4_Init(void)
{

  TIM_ClockConfigTypeDef sClockSourceConfig = {0};
  TIM_MasterConfigTypeDef sMasterConfig = {0};
  TIM_OC_InitTypeDef sConfigOC = {0};

  htim4.Instance = TIM4;
  htim4.Init.Prescaler = 33-1;
  htim4.Init.CounterMode = TIM_COUNTERMODE_UP;
  htim4.Init.Period = 32768-1;
  htim4.Init.ClockDivision = TIM_CLOCKDIVISION_DIV1;
  htim4.Init.AutoReloadPreload = TIM_AUTORELOAD_PRELOAD_ENABLE;
  if (HAL_TIM_Base_Init(&htim4) != HAL_OK)
  {
    Error_Handler();
  }
  sClockSourceConfig.ClockSource = TIM_CLOCKSOURCE_INTERNAL;
  if (HAL_TIM_ConfigClockSource(&htim4, &sClockSourceConfig) != HAL_OK)
  {
    Error_Handler();
  }
  if (HAL_TIM_PWM_Init(&htim4) != HAL_OK)
  {
    Error_Handler();
  }
  sMasterConfig.MasterOutputTrigger = TIM_TRGO_RESET;
  sMasterConfig.MasterSlaveMode = TIM_MASTERSLAVEMODE_DISABLE;
  if (HAL_TIMEx_MasterConfigSynchronization(&htim4, &sMasterConfig) != HAL_OK)
  {
    Error_Handler();
  }
  sConfigOC.OCMode = TIM_OCMODE_PWM1;
  sConfigOC.Pulse = 256;
  sConfigOC.OCPolarity = TIM_OCPOLARITY_HIGH;
  sConfigOC.OCFastMode = TIM_OCFAST_DISABLE;
  if (HAL_TIM_PWM_ConfigChannel(&htim4, &sConfigOC, TIM_CHANNEL_2) != HAL_OK)
  {
    Error_Handler();
  }
  /* USER CODE BEGIN TIM4_Init 2 */
  HAL_TIM_PWM_Start(&htim4, TIM_CHANNEL_2);
  /* USER CODE END TIM4_Init 2 */
  HAL_TIM_MspPostInit(&htim4);

}

static void MX_TIM7_Init(void)
{

  TIM_MasterConfigTypeDef sMasterConfig = {0};

  htim7.Instance = TIM7;
  htim7.Init.Prescaler = 10800-1;
  htim7.Init.CounterMode = TIM_COUNTERMODE_UP;
  htim7.Init.Period = 10000-1;
  htim7.Init.AutoReloadPreload = TIM_AUTORELOAD_PRELOAD_ENABLE;
  if (HAL_TIM_Base_Init(&htim7) != HAL_OK)
  {
    Error_Handler();
  }
  sMasterConfig.MasterOutputTrigger = TIM_TRGO_RESET;
  sMasterConfig.MasterSlaveMode = TIM_MASTERSLAVEMODE_DISABLE;
  if (HAL_TIMEx_MasterConfigSynchronization(&htim7, &sMasterConfig) != HAL_OK)
  {
    Error_Handler();
  }
  /* USER CODE BEGIN TIM7_Init 2 */
  HAL_TIM_Base_Start_IT(&htim7);
  /* USER CODE END TIM7_Init 2 */

}

static void MX_TIM14_Init(void)
{

  TIM_OC_InitTypeDef sConfigOC = {0};

  htim14.Instance = TIM14;
  htim14.Init.Prescaler = 108-1;
  htim14.Init.CounterMode = TIM_COUNTERMODE_UP;
  htim14.Init.Period = 100-1;
  htim14.Init.ClockDivision = TIM_CLOCKDIVISION_DIV1;
  htim14.Init.AutoReloadPreload = TIM_AUTORELOAD_PRELOAD_DISABLE;
  if (HAL_TIM_Base_Init(&htim14) != HAL_OK)
  {
    Error_Handler();
  }
  if (HAL_TIM_PWM_Init(&htim14) != HAL_OK)
  {
    Error_Handler();
  }
  sConfigOC.OCMode = TIM_OCMODE_PWM1;
  sConfigOC.Pulse = 100-1;
  sConfigOC.OCPolarity = TIM_OCPOLARITY_HIGH;
  sConfigOC.OCFastMode = TIM_OCFAST_DISABLE;
  if (HAL_TIM_PWM_ConfigChannel(&htim14, &sConfigOC, TIM_CHANNEL_1) != HAL_OK)
  {
    Error_Handler();
  }
  /* USER CODE BEGIN TIM14_Init 2 */
  HAL_TIM_PWM_Start(&htim14, TIM_CHANNEL_1);
  /* USER CODE END TIM14_Init 2 */
  HAL_TIM_MspPostInit(&htim14);

}

static void MX_USART1_UART_Init(void)
{

  huart1.Instance = USART1;
  huart1.Init.BaudRate = 115200;
  huart1.Init.WordLength = UART_WORDLENGTH_8B;
  huart1.Init.StopBits = UART_STOPBITS_1;
  huart1.Init.Parity = UART_PARITY_NONE;
  huart1.Init.Mode = UART_MODE_TX_RX;
  huart1.Init.HwFlowCtl = UART_HWCONTROL_NONE;
  huart1.Init.OverSampling = UART_OVERSAMPLING_16;
  huart1.Init.OneBitSampling = UART_ONE_BIT_SAMPLE_DISABLE;
  huart1.AdvancedInit.AdvFeatureInit = UART_ADVFEATURE_NO_INIT;
  if (HAL_UART_Init(&huart1) != HAL_OK)
  {
    Error_Handler();
  }

}

static void MX_USART2_UART_Init(void)
{

  huart2.Instance = USART2;
  huart2.Init.BaudRate = 38400;
  huart2.Init.WordLength = UART_WORDLENGTH_8B;
  huart2.Init.StopBits = UART_STOPBITS_1;
  huart2.Init.Parity = UART_PARITY_NONE;
  huart2.Init.Mode = UART_MODE_TX_RX;
  huart2.Init.HwFlowCtl = UART_HWCONTROL_NONE;
  huart2.Init.OverSampling = UART_OVERSAMPLING_16;
  huart2.Init.OneBitSampling = UART_ONE_BIT_SAMPLE_DISABLE;
  huart2.AdvancedInit.AdvFeatureInit = UART_ADVFEATURE_NO_INIT;
  if (HAL_UART_Init(&huart2) != HAL_OK)
  {
    Error_Handler();
  }

}

/* FMC initialization function */
static void MX_FMC_Init(void)
{

  /* USER CODE BEGIN FMC_Init 0 */
  FMC_SDRAM_CommandTypeDef Command;
  DMA_HandleTypeDef dma_handle;

  /* USER CODE END FMC_Init 0 */

  FMC_SDRAM_TimingTypeDef SdramTiming = {0};

  /** Perform the SDRAM1 memory initialization sequence
  */
  hsdram1.Instance = FMC_SDRAM_DEVICE;
  /* hsdram1.Init */
  hsdram1.Init.SDBank = FMC_SDRAM_BANK1;
  hsdram1.Init.ColumnBitsNumber = FMC_SDRAM_COLUMN_BITS_NUM_9;
  hsdram1.Init.RowBitsNumber = FMC_SDRAM_ROW_BITS_NUM_12;
  hsdram1.Init.MemoryDataWidth = FMC_SDRAM_MEM_BUS_WIDTH_16;
  hsdram1.Init.InternalBankNumber = FMC_SDRAM_INTERN_BANKS_NUM_4;
  hsdram1.Init.CASLatency = FMC_SDRAM_CAS_LATENCY_3;
  hsdram1.Init.WriteProtection = FMC_SDRAM_WRITE_PROTECTION_DISABLE;
  hsdram1.Init.SDClockPeriod = FMC_SDRAM_CLOCK_PERIOD_2;
  hsdram1.Init.ReadBurst = FMC_SDRAM_RBURST_ENABLE;
  hsdram1.Init.ReadPipeDelay = FMC_SDRAM_RPIPE_DELAY_0;
  /* SdramTiming */
  SdramTiming.LoadToActiveDelay = 2;
  SdramTiming.ExitSelfRefreshDelay = 7;
  SdramTiming.SelfRefreshTime = 7;
  SdramTiming.RowCycleDelay = 10;
  SdramTiming.WriteRecoveryTime = 4;
  SdramTiming.RPDelay = 3;
  SdramTiming.RCDDelay = 3;

  if (HAL_SDRAM_Init(&hsdram1, &SdramTiming) != HAL_OK)
  {
    Error_Handler( );
  }

  /* USER CODE BEGIN FMC_Init 2 */
  /* Step 1: Configure a clock configuration enable command */
  Command.CommandMode            = FMC_SDRAM_CMD_CLK_ENABLE;
  Command.CommandTarget          = FMC_SDRAM_CMD_TARGET_BANK1;
  Command.AutoRefreshNumber      = 1;
  Command.ModeRegisterDefinition = 0;
  HAL_SDRAM_SendCommand(&hsdram1, &Command, SDRAM_TIMEOUT);

  /* Step 2: Insert 100 us minimum delay */
  /* Inserted delay is equal to 1 ms due to systick time base unit (ms) */
  HAL_Delay(1);

  /* Step 3: Configure a PALL (precharge all) command */
  Command.CommandMode            = FMC_SDRAM_CMD_PALL;
  Command.CommandTarget          = FMC_SDRAM_CMD_TARGET_BANK1;
  Command.AutoRefreshNumber      = 1;
  Command.ModeRegisterDefinition = 0;
  HAL_SDRAM_SendCommand(&hsdram1, &Command, SDRAM_TIMEOUT);

  /* Step 4: Configure an Auto Refresh command */
  Command.CommandMode            = FMC_SDRAM_CMD_AUTOREFRESH_MODE;
  Command.CommandTarget          = FMC_SDRAM_CMD_TARGET_BANK1;
  Command.AutoRefreshNumber      = 8;
  Command.ModeRegisterDefinition = 0;
  HAL_SDRAM_SendCommand(&hsdram1, &Command, SDRAM_TIMEOUT);

  /* Step 5: Program the external memory mode register */
  __IO uint32_t tmpmrd = (uint32_t)SDRAM_MODEREG_BURST_LENGTH_1          |\
                                   SDRAM_MODEREG_BURST_TYPE_SEQUENTIAL   |\
                                   SDRAM_MODEREG_CAS_LATENCY_3           |\
                                   SDRAM_MODEREG_OPERATING_MODE_STANDARD |\
                                   SDRAM_MODEREG_WRITEBURST_MODE_SINGLE;

  Command.CommandMode            = FMC_SDRAM_CMD_LOAD_MODE;
  Command.CommandTarget          = FMC_SDRAM_CMD_TARGET_BANK1;
  Command.AutoRefreshNumber      = 1;
  Command.ModeRegisterDefinition = tmpmrd;
  HAL_SDRAM_SendCommand(&hsdram1, &Command, SDRAM_TIMEOUT);

  /* Step 6: Set the refresh rate counter */
  /* Set the device refresh rate */
  HAL_SDRAM_ProgramRefreshRate(&hsdram1, REFRESH_COUNT);

  /* Configure common DMA parameters */
  dma_handle.Init.Channel             = SDRAM_DMAx_CHANNEL;
  dma_handle.Init.Direction           = DMA_MEMORY_TO_MEMORY;
  dma_handle.Init.PeriphInc           = DMA_PINC_ENABLE;
  dma_handle.Init.MemInc              = DMA_MINC_ENABLE;
  dma_handle.Init.PeriphDataAlignment = DMA_PDATAALIGN_WORD;
  dma_handle.Init.MemDataAlignment    = DMA_MDATAALIGN_WORD;
  dma_handle.Init.Mode                = DMA_NORMAL;
  dma_handle.Init.Priority            = DMA_PRIORITY_HIGH;
  dma_handle.Init.FIFOMode            = DMA_FIFOMODE_DISABLE;
  dma_handle.Init.FIFOThreshold       = DMA_FIFO_THRESHOLD_FULL;
  dma_handle.Init.MemBurst            = DMA_MBURST_SINGLE;
  dma_handle.Init.PeriphBurst         = DMA_PBURST_SINGLE;

  dma_handle.Instance = SDRAM_DMAx_STREAM;

   /* Associate the DMA handle */
  __HAL_LINKDMA(&hsdram1, hdma, dma_handle);

  /* Deinitialize the stream for new transfer */
  HAL_DMA_DeInit(&dma_handle);

  /* Configure the DMA stream */
  HAL_DMA_Init(&dma_handle);

  /* NVIC configuration for DMA transfer complete interrupt */
  HAL_NVIC_SetPriority(SDRAM_DMAx_IRQn, 0x0F, 0);
  HAL_NVIC_EnableIRQ(SDRAM_DMAx_IRQn);

  /* USER CODE END FMC_Init 2 */
}

static void MX_GPIO_Init(void)
{
  GPIO_InitTypeDef GPIO_InitStruct = {0};

  /* GPIO Ports Clock Enable */
  __HAL_RCC_GPIOE_CLK_ENABLE();
  __HAL_RCC_GPIOB_CLK_ENABLE();
  __HAL_RCC_GPIOC_CLK_ENABLE();
  __HAL_RCC_GPIOA_CLK_ENABLE();
  __HAL_RCC_GPIOG_CLK_ENABLE();
  __HAL_RCC_GPIOJ_CLK_ENABLE();
  __HAL_RCC_GPIOD_CLK_ENABLE();
  __HAL_RCC_GPIOK_CLK_ENABLE();
  __HAL_RCC_GPIOF_CLK_ENABLE();
  __HAL_RCC_GPIOI_CLK_ENABLE();
  __HAL_RCC_GPIOH_CLK_ENABLE();

  /*Configure GPIO pin Output Level */
  HAL_GPIO_WritePin(GPIOE, BUZZER_ON_Pin|LED_ON_Pin, GPIO_PIN_RESET);

  /*Configure GPIO pin Output Level */
  HAL_GPIO_WritePin(LED_RG_CTL_GPIO_Port, LED_RG_CTL_Pin, GPIO_PIN_RESET);

  /*Configure GPIO pin Output Level */
  HAL_GPIO_WritePin(GPIOA, CAN1_STBY_Pin|TS_INT_Pin|LCD_STBY_Pin|TS_RSTn_Pin
                          |LCD_RSTn_Pin, GPIO_PIN_RESET);

  /*Configure GPIO pin Output Level */
  HAL_GPIO_WritePin(GPIOA, LCD_LR_Pin|LCD_UD_Pin, GPIO_PIN_SET);

  /*Configure GPIO pin Output Level */
  HAL_GPIO_WritePin(PWR_HOLD_GPIO_Port, PWR_HOLD_Pin, GPIO_PIN_RESET);

  /*Configure GPIO pin : BUZZER_ON_Pin */
  GPIO_InitStruct.Pin = BUZZER_ON_Pin;
  GPIO_InitStruct.Mode = GPIO_MODE_OUTPUT_PP;
  GPIO_InitStruct.Pull = GPIO_NOPULL;
  GPIO_InitStruct.Speed = GPIO_SPEED_FREQ_HIGH;
  HAL_GPIO_Init(BUZZER_ON_GPIO_Port, &GPIO_InitStruct);

  /*Configure GPIO pin : LED_ON_Pin */
  GPIO_InitStruct.Pin = LED_ON_Pin;
  GPIO_InitStruct.Mode = GPIO_MODE_OUTPUT_PP;
  GPIO_InitStruct.Pull = GPIO_NOPULL;
  GPIO_InitStruct.Speed = GPIO_SPEED_FREQ_LOW;
  HAL_GPIO_Init(LED_ON_GPIO_Port, &GPIO_InitStruct);

  /*Configure GPIO pin : LED_RG_CTL_Pin */
  GPIO_InitStruct.Pin = LED_RG_CTL_Pin;
  GPIO_InitStruct.Mode = GPIO_MODE_OUTPUT_PP;
  GPIO_InitStruct.Pull = GPIO_NOPULL;
  GPIO_InitStruct.Speed = GPIO_SPEED_FREQ_LOW;
  HAL_GPIO_Init(LED_RG_CTL_GPIO_Port, &GPIO_InitStruct);

  /*Configure GPIO pins : KEY_DN_Pin KEY_SEL_Pin KEY_UP_Pin KEY_PREV_Pin */
  GPIO_InitStruct.Pin = KEY_DN_Pin|KEY_SEL_Pin|KEY_UP_Pin|KEY_PREV_Pin;
  GPIO_InitStruct.Mode = GPIO_MODE_INPUT;
  GPIO_InitStruct.Pull = GPIO_NOPULL;
  HAL_GPIO_Init(GPIOC, &GPIO_InitStruct);

  /*Configure GPIO pin : PWR_ON_Pin */
  GPIO_InitStruct.Pin = PWR_ON_Pin;
  GPIO_InitStruct.Mode = GPIO_MODE_INPUT;
  GPIO_InitStruct.Pull = GPIO_NOPULL;
  HAL_GPIO_Init(PWR_ON_GPIO_Port, &GPIO_InitStruct);

  /*Configure GPIO pin : KEY_PWR_Pin */
  GPIO_InitStruct.Pin = KEY_PWR_Pin;
  GPIO_InitStruct.Mode = GPIO_MODE_INPUT;
  GPIO_InitStruct.Pull = GPIO_PULLUP;
  HAL_GPIO_Init(KEY_PWR_GPIO_Port, &GPIO_InitStruct);

  /*Configure GPIO pins : CAN1_STBY_Pin LCD_LR_Pin LCD_UD_Pin TS_INT_Pin
                           LCD_STBY_Pin TS_RSTn_Pin LCD_RSTn_Pin */
  GPIO_InitStruct.Pin = CAN1_STBY_Pin|LCD_LR_Pin|LCD_UD_Pin|TS_INT_Pin
                          |LCD_STBY_Pin|TS_RSTn_Pin|LCD_RSTn_Pin;
  GPIO_InitStruct.Mode = GPIO_MODE_OUTPUT_PP;
  GPIO_InitStruct.Pull = GPIO_NOPULL;
  GPIO_InitStruct.Speed = GPIO_SPEED_FREQ_LOW;
  HAL_GPIO_Init(GPIOA, &GPIO_InitStruct);

  /*Configure GPIO pin : PWR_HOLD_Pin */
  GPIO_InitStruct.Pin = PWR_HOLD_Pin;
  GPIO_InitStruct.Mode = GPIO_MODE_OUTPUT_PP;
  GPIO_InitStruct.Pull = GPIO_NOPULL;
  GPIO_InitStruct.Speed = GPIO_SPEED_FREQ_LOW;
  HAL_GPIO_Init(PWR_HOLD_GPIO_Port, &GPIO_InitStruct);

}

__weak void runEcoTaskMain(void *argument)
{
  for(;;)
  {
    osDelay(1);
  }
}

void HAL_TIM_PeriodElapsedCallback(TIM_HandleTypeDef *htim)
{
  if (htim->Instance == TIM6)
  {
    HAL_IncTick();
  }
  /* USER CODE BEGIN Callback 1 */
  if (htim->Instance == TIM7)
  {
//    printf("TIM7\n");
  }

  /* USER CODE END Callback 1 */
}

void Error_Handler(void)
{
  __disable_irq();
  while (1)
  {
  }
}
